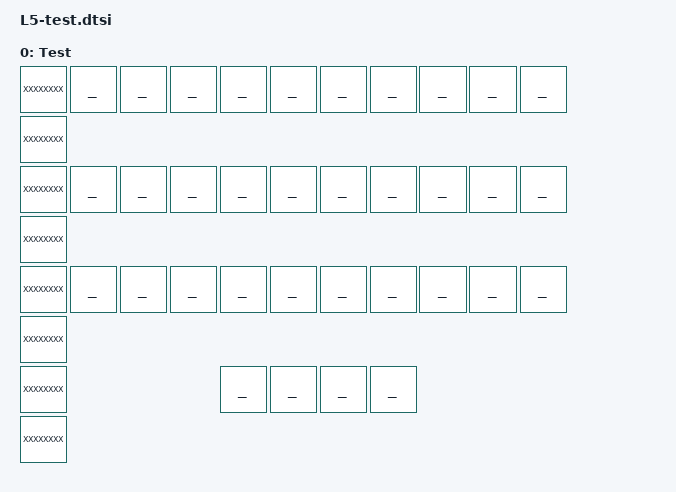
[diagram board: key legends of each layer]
/**
 *
 */

/ {
  keymap {
    compatible = "zmk,keymap";

	test_layer {
		label = "Test";
		bindings = <
//					╭───────────────┬───────────────┬───────────────┬───────────────┬───────────────╮   ╭───────────────┬───────────────┬───────────────┬───────────────┬───────────────╮
	XXXXXXXX			________		________    	________		________		________			________        ________     	________        ________        ________
	XXXXXXXX	//	├───────────────┼───────────────┼───────────────┼───────────────┼───────────────┤   ├───────────────├───────────────┼───────────────┼───────────────┼───────────────┤
	XXXXXXXX			________		________    	________		________		________			________        ________     	________        ________        ________
	XXXXXXXX	//	├───────────────┼───────────────┼───────────────┼───────────────┼───────────────┤   ├───────────────├───────────────┼───────────────┼───────────────┼───────────────┤
	XXXXXXXX			________		________        ________        ________		________            ________        ________     	________        ________        ________
	XXXXXXXX	//	╰───────────────┴───────────────┼───────────────┼───────────────┼───────────────┤   ├───────────────├───────────────┼───────────────┼───────────────┴───────────────╯
	XXXXXXXX       														________        ________           	________		________
//                                                                  ╰───────────────┴───────────────╯   ╰───────────────┴───────────────╯
	XXXXXXXX
			>;
		};
	};
};
